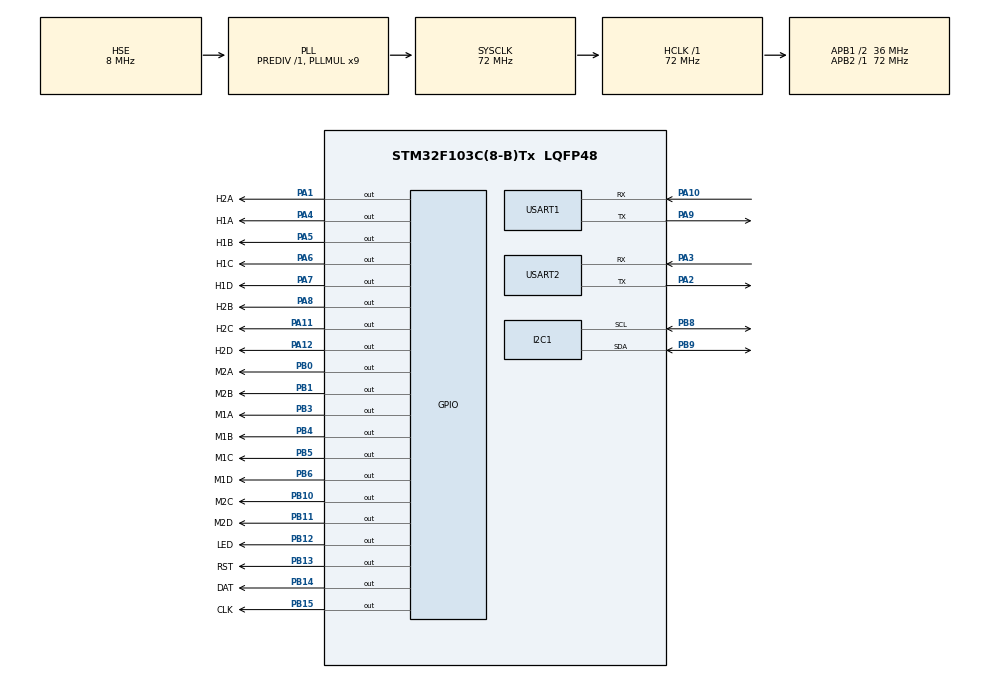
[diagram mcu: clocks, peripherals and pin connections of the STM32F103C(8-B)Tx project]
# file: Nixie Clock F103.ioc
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Mcu.Family=STM32F1
Mcu.Name=STM32F103C(8-B)Tx
Mcu.Package=LQFP48
NVIC.PriorityGroup=NVIC_PRIORITYGROUP_4
PA1.GPIO_Label=H2A
PA1.GPIO_Speed=GPIO_SPEED_FREQ_HIGH
PA1.PinState=GPIO_PIN_SET
PA1.Signal=GPIO_Output
PA10.Mode=Asynchronous
PA10.Signal=USART1_RX
PA11.GPIO_Label=H2C
PA11.GPIO_Speed=GPIO_SPEED_FREQ_HIGH
PA11.PinState=GPIO_PIN_SET
PA11.Signal=GPIO_Output
PA12.GPIO_Label=H2D
PA12.GPIO_Speed=GPIO_SPEED_FREQ_HIGH
PA12.PinState=GPIO_PIN_SET
PA12.Signal=GPIO_Output
PA13.Mode=Serial_Wire
PA13.Signal=SYS_JTMS-SWDIO
PA14.Mode=Serial_Wire
PA14.Signal=SYS_JTCK-SWCLK
PA2.Mode=Asynchronous
PA2.Signal=USART2_TX
PA3.Mode=Asynchronous
PA3.Signal=USART2_RX
PA4.GPIO_Label=H1A
PA4.GPIO_Speed=GPIO_SPEED_FREQ_HIGH
PA4.PinState=GPIO_PIN_SET
PA4.Signal=GPIO_Output
PA5.GPIO_Label=H1B
PA5.GPIO_Speed=GPIO_SPEED_FREQ_HIGH
PA5.PinState=GPIO_PIN_SET
PA5.Signal=GPIO_Output
PA6.GPIO_Label=H1C
PA6.GPIO_Speed=GPIO_SPEED_FREQ_HIGH
PA6.PinState=GPIO_PIN_SET
PA6.Signal=GPIO_Output
PA7.GPIO_Label=H1D
PA7.GPIO_Speed=GPIO_SPEED_FREQ_HIGH
PA7.PinState=GPIO_PIN_SET
PA7.Signal=GPIO_Output
PA8.GPIO_Label=H2B
PA8.GPIO_Speed=GPIO_SPEED_FREQ_HIGH
PA8.PinState=GPIO_PIN_SET
PA8.Signal=GPIO_Output
PA9.Mode=Asynchronous
PA9.Signal=USART1_TX
PB0.GPIO_Label=M2A
PB0.GPIO_Speed=GPIO_SPEED_FREQ_HIGH
PB0.PinState=GPIO_PIN_SET
PB0.Signal=GPIO_Output
PB1.GPIO_Label=M2B
PB1.GPIO_Speed=GPIO_SPEED_FREQ_HIGH
PB1.PinState=GPIO_PIN_SET
PB1.Signal=GPIO_Output
PB10.GPIO_Label=M2C
PB10.GPIO_Speed=GPIO_SPEED_FREQ_HIGH
PB10.PinState=GPIO_PIN_SET
PB10.Signal=GPIO_Output
PB11.GPIO_Label=M2D
PB11.GPIO_Speed=GPIO_SPEED_FREQ_HIGH
PB11.PinState=GPIO_PIN_SET
PB11.Signal=GPIO_Output
PB12.GPIO_Label=LED
PB12.Signal=GPIO_Output
PB13.GPIO_Label=RST
PB13.Signal=GPIO_Output
PB14.GPIO_Label=DAT
PB14.GPIO_Speed=GPIO_SPEED_FREQ_HIGH
PB14.Signal=GPIO_Output
PB15.GPIO_Label=CLK
PB15.GPIO_Speed=GPIO_SPEED_FREQ_HIGH
PB15.Signal=GPIO_Output
PB3.GPIO_Label=M1A
PB3.GPIO_Speed=GPIO_SPEED_FREQ_HIGH
PB3.PinState=GPIO_PIN_SET
PB3.Signal=GPIO_Output
PB4.GPIO_Label=M1B
PB4.GPIO_Speed=GPIO_SPEED_FREQ_HIGH
PB4.PinState=GPIO_PIN_SET
PB4.Signal=GPIO_Output
PB5.GPIO_Label=M1C
PB5.GPIO_Speed=GPIO_SPEED_FREQ_HIGH
PB5.PinState=GPIO_PIN_SET
PB5.Signal=GPIO_Output
PB6.GPIO_Label=M1D
PB6.GPIO_Speed=GPIO_SPEED_FREQ_HIGH
PB6.PinState=GPIO_PIN_SET
PB6.Signal=GPIO_Output
PB8.Mode=I2C
PB8.Signal=I2C1_SCL
PB9.Mode=I2C
PB9.Signal=I2C1_SDA
PC14-OSC32_IN.Mode=LSE-External-Oscillator
PC14-OSC32_IN.Signal=RCC_OSC32_IN
PC15-OSC32_OUT.Mode=LSE-External-Oscillator
PC15-OSC32_OUT.Signal=RCC_OSC32_OUT
PD0-OSC_IN.Mode=HSE-External-Oscillator
PD0-OSC_IN.Signal=RCC_OSC_IN
PD1-OSC_OUT.Mode=HSE-External-Oscillator
PD1-OSC_OUT.Signal=RCC_OSC_OUT
ProjectManager.HeapSize=0x200
ProjectManager.StackSize=0x400
ProjectManager.TargetToolchain=MDK-ARM V5.27
RCC.AHBFreq_Value=72000000
RCC.APB1CLKDivider=RCC_HCLK_DIV2
RCC.APB1Freq_Value=36000000
RCC.APB1TimFreq_Value=72000000
RCC.APB2Freq_Value=72000000
RCC.APB2TimFreq_Value=72000000
RCC.HCLKFreq_Value=72000000
RCC.PLLMUL=RCC_PLL_MUL9
RCC.PLLSourceVirtual=RCC_PLLSOURCE_HSE
RCC.SYSCLKFreq_VALUE=72000000
RCC.SYSCLKSource=RCC_SYSCLKSOURCE_PLLCLK
RCC.USBFreq_Value=72000000
USART1.VirtualMode=VM_ASYNC
USART2.VirtualMode=VM_ASYNC
board=custom

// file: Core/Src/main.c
/* USER CODE BEGIN Header */
/**
  ******************************************************************************
  * @file           : main.c
  * @brief          : Main program body
  ******************************************************************************
  * @attention
  *
  * <h2><center>&copy; Copyright (c) 2021 STMicroelectronics.
  * All rights reserved.</center></h2>
  *
  * This software component is licensed by ST under BSD 3-Clause license,
  * the "License"; You may not use this file except in compliance with the
  * License. You may obtain a copy of the License at:
  *                        opensource.org/licenses/BSD-3-Clause
  *
  ******************************************************************************
  */
/* USER CODE END Header */
#include "main.h"
#include "i2c.h"
#include "usart.h"
#include "gpio.h"

/* USER CODE BEGIN Includes */
#include "stdio.h"
#include "DS1302.h"
#include "NixieTube.h"
/* USER CODE END Includes */

/* USER CODE BEGIN PD */
#define Delay HAL_Delay(1000)
/* USER CODE END PD */

void SystemClock_Config(void);

int main(void)
{

  /* MCU Configuration--------------------------------------------------------*/

  /* Reset of all peripherals, Initializes the Flash interface and the Systick. */
  HAL_Init();

  /* Configure the system clock */
  SystemClock_Config();

  /* Initialize all configured peripherals */
  MX_GPIO_Init();
  MX_USART1_UART_Init();
  MX_USART2_UART_Init();
  MX_I2C1_Init();
  /* USER CODE BEGIN 2 */
    DS1302_WriteTime();

  /* USER CODE END 2 */

  /* Infinite loop */
  /* USER CODE BEGIN WHILE */
  while (1)
  {
      DS1302_GetTime();
    //printf("%d\r\n",timedata.year);
    //printf("%d:%d:%d\r\n",timedata.year,timedata.month,timedata.day);
    printf("%d:%d:%d\r\n",timedata.hour,timedata.minute,timedata.second);
    Test();
    //ShowTime(timedata.hour,timedata.minute);
      HAL_Delay(3000);
    /* USER CODE END WHILE */
  }
}

void SystemClock_Config(void)
{
  RCC_OscInitTypeDef RCC_OscInitStruct = {0};
  RCC_ClkInitTypeDef RCC_ClkInitStruct = {0};

  /** Initializes the RCC Oscillators according to the specified parameters
  * in the RCC_OscInitTypeDef structure.
  */
  RCC_OscInitStruct.OscillatorType = RCC_OSCILLATORTYPE_HSE;
  RCC_OscInitStruct.HSEState = RCC_HSE_ON;
  RCC_OscInitStruct.HSEPredivValue = RCC_HSE_PREDIV_DIV1;
  RCC_OscInitStruct.HSIState = RCC_HSI_ON;
  RCC_OscInitStruct.PLL.PLLState = RCC_PLL_ON;
  RCC_OscInitStruct.PLL.PLLSource = RCC_PLLSOURCE_HSE;
  RCC_OscInitStruct.PLL.PLLMUL = RCC_PLL_MUL9;
  if (HAL_RCC_OscConfig(&RCC_OscInitStruct) != HAL_OK)
  {
    Error_Handler();
  }
  /** Initializes the CPU, AHB and APB buses clocks
  */
  RCC_ClkInitStruct.ClockType = RCC_CLOCKTYPE_HCLK|RCC_CLOCKTYPE_SYSCLK
                              |RCC_CLOCKTYPE_PCLK1|RCC_CLOCKTYPE_PCLK2;
  RCC_ClkInitStruct.SYSCLKSource = RCC_SYSCLKSOURCE_PLLCLK;
  RCC_ClkInitStruct.AHBCLKDivider = RCC_SYSCLK_DIV1;
  RCC_ClkInitStruct.APB1CLKDivider = RCC_HCLK_DIV2;
  RCC_ClkInitStruct.APB2CLKDivider = RCC_HCLK_DIV1;

  if (HAL_RCC_ClockConfig(&RCC_ClkInitStruct, FLASH_LATENCY_2) != HAL_OK)
  {
    Error_Handler();
  }
}

void Error_Handler(void)
{
  __disable_irq();
  while (1)
  {
  }
}

/************************ (C) COPYRIGHT STMicroelectronics *****END OF FILE****/
